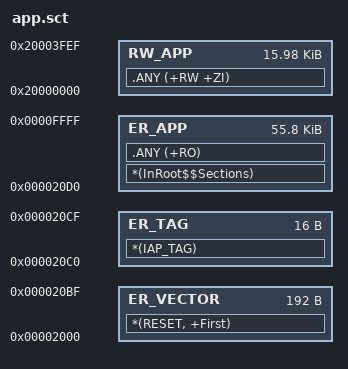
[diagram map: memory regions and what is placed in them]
LR_APP 0x00002000 0x0000E000 {
  ER_VECTOR 0x00002000 0x000000C0 { *(RESET, +First) }
  ER_TAG 0x000020C0 0x00000010 { *(IAP_TAG) }
  ER_APP 0x000020D0 0x0000DF30 {
    *(InRoot$$Sections)
    .ANY (+RO)
  }
  RW_APP 0x20000000 0x00003FF0 { .ANY (+RW +ZI) }
}
